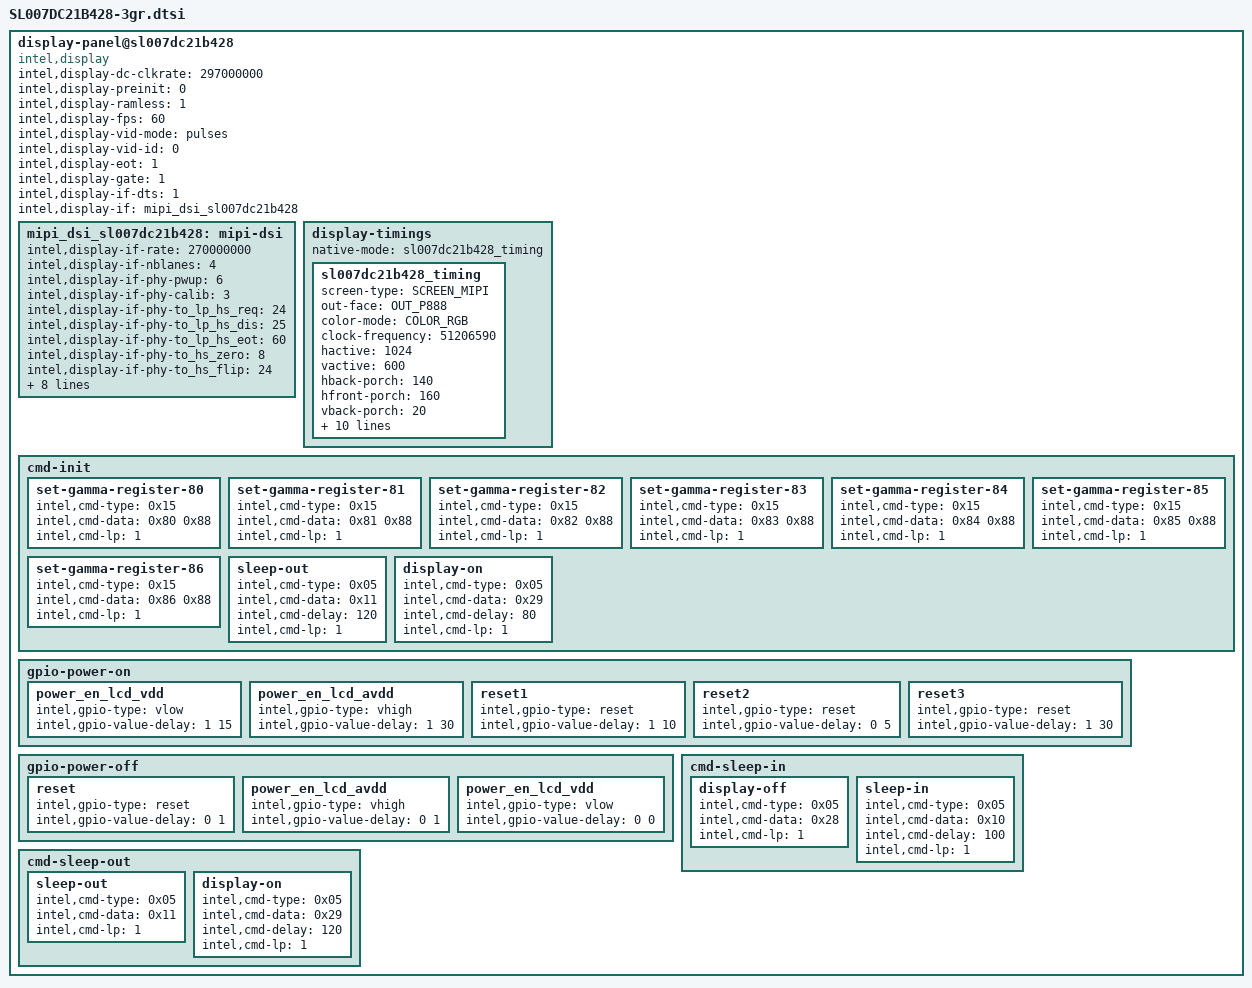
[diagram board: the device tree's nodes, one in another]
/*
 * definition at "include/dt-bindings/sofiafb/sofia_fb.h"
 */

display-panel@sl007dc21b428 {
	compatible = "intel,display";
	intel,display-dc-clkrate = <297000000>;
	intel,display-preinit = <0>;
	intel,display-ramless = <1>;
	intel,display-fps = <60>;
	intel,display-vid-mode = "pulses";
	intel,display-vid-id = <0>;
	intel,display-eot = <1>;
	intel,display-gate = <1>;
	intel,display-if-dts = <1>;
	intel,display-if = <&mipi_dsi_sl007dc21b428>;
	mipi_dsi_sl007dc21b428:mipi-dsi {
		intel,display-if-rate = <270000000>;
		intel,display-if-nblanes = <4>;
		intel,display-if-phy-pwup = <6>;
		intel,display-if-phy-calib = <3>;
		intel,display-if-phy-to_lp_hs_req = <24>;
		intel,display-if-phy-to_lp_hs_dis = <25>;
		intel,display-if-phy-to_lp_hs_eot = <60>;
		intel,display-if-phy-to_hs_zero = <8>;
		intel,display-if-phy-to_hs_flip = <24>;
		intel,display-if-phy-lp_clk_div = <31>;
		intel,display-if-phy-to_hs_clk_pre = <36>;
		intel,display-if-phy-to_hs_clk_post = <42>;
		intel,display-if-phy-data_delay = <7>;
		intel,display-if-phy-clock_delay = <7>;
		intel,display-if-phy-lp_tx_tfall = <2>;
		intel,display-if-phy-lp_tx_rise = <2>;
		intel,display-if-phy-lp_tx_vref = <31>;
	};

	display-timings {
		native-mode = <&sl007dc21b428_timing>;
		sl007dc21b428_timing: sl007dc21b428_timing {
			screen-type = <SCREEN_MIPI>;
			out-face    = <OUT_P888>;
			color-mode = <COLOR_RGB>;
			clock-frequency = <51206590>;
			hactive = <1024>;
			vactive = <600>;
			hback-porch = <140>;
			hfront-porch = <160>;
			vback-porch = <20>;
			vfront-porch = <12>;
			hsync-len = <20>;
			vsync-len = <3>;
			hsync-active = <0>;
			vsync-active = <0>;
			de-active = <0>;
			pixelclk-active = <0>;
			swap-rb = <0>;
			swap-rg = <0>;
			swap-gb = <0>;
		};
	};

		cmd-init {
/*
 			set-register-25-s {
				intel,cmd-type = <0x15>;
				intel,cmd-data = <0x25 0x55>;
				intel,cmd-lp = <1>;
			};
*/
			set-gamma-register-80 {
				intel,cmd-type = <0x15>;
				intel,cmd-data = <0x80 0x88>;
				intel,cmd-lp = <1>;
			};
			set-gamma-register-81 {
				intel,cmd-type = <0x15>;
				intel,cmd-data = <0x81 0x88>;
				intel,cmd-lp = <1>;
			};
			set-gamma-register-82 {
				intel,cmd-type = <0x15>;
				intel,cmd-data = <0x82 0x88>;
				intel,cmd-lp = <1>;
			};
			set-gamma-register-83 {
				intel,cmd-type = <0x15>;
				intel,cmd-data = <0x83 0x88>;
				intel,cmd-lp = <1>;
			};
			set-gamma-register-84 {
				intel,cmd-type = <0x15>;
				intel,cmd-data = <0x84 0x88>;
				intel,cmd-lp = <1>;
			};
			set-gamma-register-85 {
				intel,cmd-type = <0x15>;
				intel,cmd-data = <0x85 0x88>;
				intel,cmd-lp = <1>;
			};
			set-gamma-register-86 {
				intel,cmd-type = <0x15>;
				intel,cmd-data = <0x86 0x88>;
				intel,cmd-lp = <1>;
			};
/*
 			set-register-25-e {
				intel,cmd-type = <0x15>;
				intel,cmd-data = <0x25 0x00>;
				intel,cmd-lp = <1>;
			};
*/
			sleep-out {
				intel,cmd-type = <0x05>;
				intel,cmd-data = <0x11>;
				intel,cmd-delay = <120>;
				intel,cmd-lp = <1>;
			};
			display-on {
				intel,cmd-type = <0x05>;
				intel,cmd-data = <0x29>;
				intel,cmd-delay = <80>;
				intel,cmd-lp = <1>;
			};
		};

		gpio-power-on {
			power_en_lcd_vdd {
				intel,gpio-type = "vlow";
				intel,gpio-value-delay = <1 15>;
			};
			power_en_lcd_avdd {
				intel,gpio-type = "vhigh";
				intel,gpio-value-delay = <1 30>;
			};
			reset1 {
				intel,gpio-type = "reset";
				intel,gpio-value-delay = <1 10>;
			};
			reset2 {
				intel,gpio-type = "reset";
				intel,gpio-value-delay = <0 5>;
			};
			reset3 {
				intel,gpio-type = "reset";
				intel,gpio-value-delay = <1 30>;
			};
		};

		gpio-power-off {
			reset {
				intel,gpio-type = "reset";
				intel,gpio-value-delay = <0 1>;
			};
			power_en_lcd_avdd {
				intel,gpio-type = "vhigh";
				intel,gpio-value-delay = <0 1>;
			};
			power_en_lcd_vdd {
				intel,gpio-type = "vlow";
				intel,gpio-value-delay = <0 0>;
			};

		};

		cmd-sleep-in {
			display-off {
				intel,cmd-type = <0x05>;
				intel,cmd-data = <0x28>;
				intel,cmd-lp = <1>;
			};
			sleep-in {
				intel,cmd-type = <0x05>;
				intel,cmd-data = <0x10>;
				intel,cmd-delay = <100>;
				intel,cmd-lp = <1>;
			};
		};

		cmd-sleep-out {
			sleep-out {
				intel,cmd-type = <0x05>;
				intel,cmd-data = <0x11>;
				intel,cmd-lp = <1>;
			};
			display-on {
				intel,cmd-type = <0x05>;
				intel,cmd-data = <0x29>;
				intel,cmd-delay = <120>;
				intel,cmd-lp = <1>;
			};
		};
	};
